AUTOSAR XML (schema 4-3-0)
package /BcmSystem/SwComponentTypes
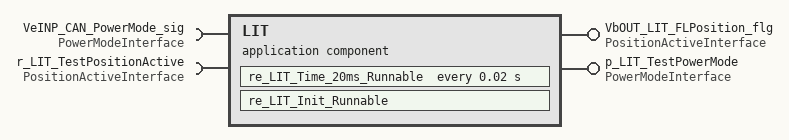
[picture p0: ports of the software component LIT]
  application sw component type LIT
    require port VeINP_CAN_PowerMode_sig: required-interface=PowerModeInterface
    provide port VbOUT_LIT_FLPosition_flg: provided-interface=PositionActiveInterface
    provide port p_LIT_TestPowerMode: provided-interface=PowerModeInterface
    require port r_LIT_TestPositionActive: required-interface=PositionActiveInterface
    behavior LIT_IB: handle-termination-and-restart=NO-SUPPORT
      init event ie_LIT_Init_Runnable: start-on-event=re_LIT_Init_Runnable
      timing event te_LIT_Time_10ms_Runnable: start-on-event=re_LIT_Time_20ms_Runnable, period=0.02
      runnable re_LIT_Init_Runnable: symbol=LIT_Init_Runnable
      runnable re_LIT_Time_20ms_Runnable: symbol=LIT_Time_20ms_Runnable
package /BcmSystem/SwImplementations
  swc implementation SwcImpLIT: programming-language=C, sw-version=1.0.0, vendor-id=0, behavior=LIT_IB
    code-descriptors:
      code CodeLIT: artifact-descriptors=autosar-engineering-object={short-label=SwSrcLIT, category=SWSRC}
